# ATSAM3A4C device description
Architecture: CORTEX-M3; Family: SAM3; Series: SAM3XA
Registers are 32-bit, read-write, no defined reset value unless marked. A register's access mark holds for its fields unless they carry their own. Offsets are from the block's base; [hi:lo] are bit positions; {n}, {i} and the like mark numbered series; 'fields as' and 'values as' point back to an identical list.

## UOTGHS — USB On-The-Go Interface
Instances: UOTGHS 0x400AC000
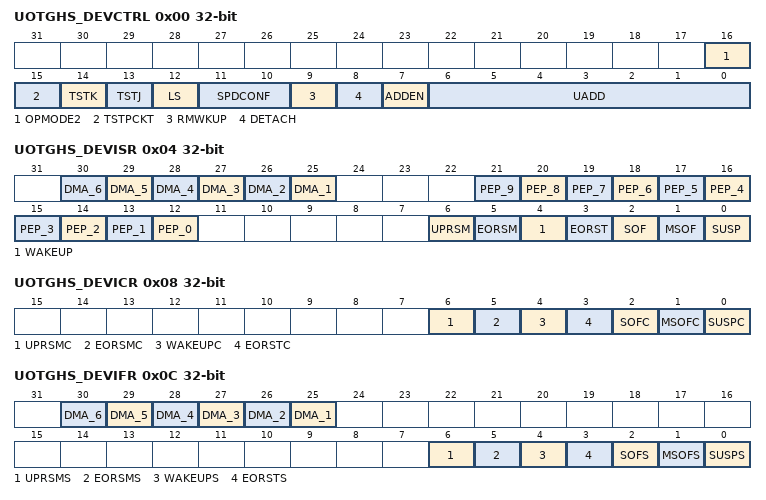
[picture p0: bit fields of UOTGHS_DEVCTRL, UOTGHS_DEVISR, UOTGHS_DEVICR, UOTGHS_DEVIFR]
0x00 UOTGHS_DEVCTRL — Device General Control Register
  [16] OPMODE2 — Specific Operational mode
  [15] TSTPCKT — Test packet mode
  [14] TSTK — Test mode K
  [13] TSTJ — Test mode J
  [12] LS — Low-Speed Mode Force
  [11:10] SPDCONF — Mode Configuration
    0=NORMAL (The peripheral starts in full-speed mode and performs a high-speed reset to switch to the high-speed mode if the host is high-speed capable.); 1=LOW_POWER (For a better consumption, if high-speed is not needed.); 2=HIGH_SPEED (Forced high speed.); 3=FORCED_FS (The peripheral remains in full-speed mode whatever the host speed capability.)
  [9] RMWKUP — Remote Wake-Up
  [8] DETACH
  [7] ADDEN — Address Enable
  [6:0] UADD — USB Address
0x04 UOTGHS_DEVISR ro — Device Global Interrupt Status Register
  [n+24] DMA_{n} (n=1..6) — DMA Channel {n} Interrupt
  [n+12] PEP_{n} (n=0..9) — Endpoint {n} Interrupt
  [6] UPRSM — Upstream Resume Interrupt
  [5] EORSM — End of Resume Interrupt
  [4] WAKEUP — Wake-Up Interrupt
  [3] EORST — End of Reset Interrupt
  [2] SOF — Start of Frame Interrupt
  [1] MSOF — Micro Start of Frame Interrupt
  [0] SUSP — Suspend Interrupt
0x08 UOTGHS_DEVICR wo — Device Global Interrupt Clear Register
  [6] UPRSMC — Upstream Resume Interrupt Clear
  [5] EORSMC — End of Resume Interrupt Clear
  [4] WAKEUPC — Wake-Up Interrupt Clear
  [3] EORSTC — End of Reset Interrupt Clear
  [2] SOFC — Start of Frame Interrupt Clear
  [1] MSOFC — Micro Start of Frame Interrupt Clear
  [0] SUSPC — Suspend Interrupt Clear
0x0C UOTGHS_DEVIFR wo — Device Global Interrupt Set Register
  [n+24] DMA_{n} (n=1..6) — DMA Channel {n} Interrupt Set
  [6] UPRSMS — Upstream Resume Interrupt Set
  [5] EORSMS — End of Resume Interrupt Set
  [4] WAKEUPS — Wake-Up Interrupt Set
  [3] EORSTS — End of Reset Interrupt Set
  [2] SOFS — Start of Frame Interrupt Set
  [1] MSOFS — Micro Start of Frame Interrupt Set
  [0] SUSPS — Suspend Interrupt Set
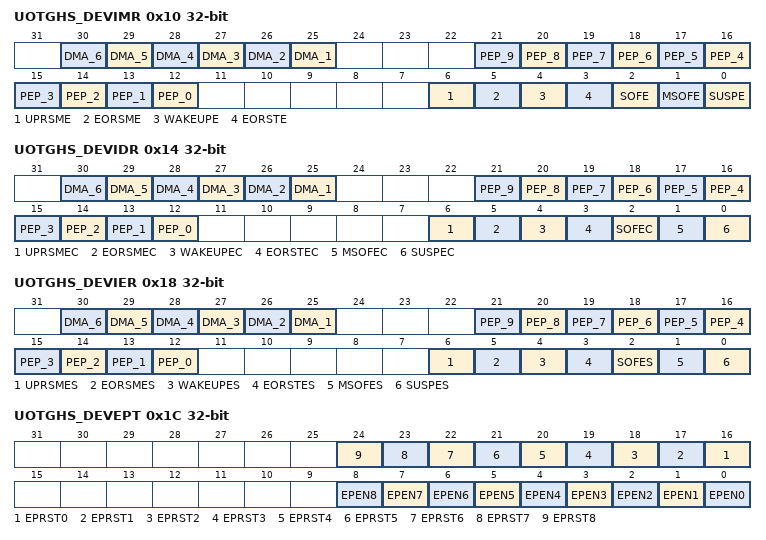
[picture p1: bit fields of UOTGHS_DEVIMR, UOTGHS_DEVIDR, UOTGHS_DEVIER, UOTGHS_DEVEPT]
0x10 UOTGHS_DEVIMR ro — Device Global Interrupt Mask Register
  [n+24] DMA_{n} (n=1..6) — DMA Channel {n} Interrupt Mask
  [n+12] PEP_{n} (n=0..9) — Endpoint {n} Interrupt Mask
  [6] UPRSME — Upstream Resume Interrupt Mask
  [5] EORSME — End of Resume Interrupt Mask
  [4] WAKEUPE — Wake-Up Interrupt Mask
  [3] EORSTE — End of Reset Interrupt Mask
  [2] SOFE — Start of Frame Interrupt Mask
  [1] MSOFE — Micro Start of Frame Interrupt Mask
  [0] SUSPE — Suspend Interrupt Mask
0x14 UOTGHS_DEVIDR wo — Device Global Interrupt Disable Register
  [n+24] DMA_{n} (n=1..6) — DMA Channel {n} Interrupt Disable
  [n+12] PEP_{n} (n=0..9) — Endpoint {n} Interrupt Disable
  [6] UPRSMEC — Upstream Resume Interrupt Disable
  [5] EORSMEC — End of Resume Interrupt Disable
  [4] WAKEUPEC — Wake-Up Interrupt Disable
  [3] EORSTEC — End of Reset Interrupt Disable
  [2] SOFEC — Start of Frame Interrupt Disable
  [1] MSOFEC — Micro Start of Frame Interrupt Disable
  [0] SUSPEC — Suspend Interrupt Disable
0x18 UOTGHS_DEVIER wo — Device Global Interrupt Enable Register
  [n+24] DMA_{n} (n=1..6) — DMA Channel {n} Interrupt Enable
  [n+12] PEP_{n} (n=0..9) — Endpoint {n} Interrupt Enable
  [6] UPRSMES — Upstream Resume Interrupt Enable
  [5] EORSMES — End of Resume Interrupt Enable
  [4] WAKEUPES — Wake-Up Interrupt Enable
  [3] EORSTES — End of Reset Interrupt Enable
  [2] SOFES — Start of Frame Interrupt Enable
  [1] MSOFES — Micro Start of Frame Interrupt Enable
  [0] SUSPES — Suspend Interrupt Enable
0x1C UOTGHS_DEVEPT — Device Endpoint Register
  [n+16] EPRST{n} (n=0..8) — Endpoint {n} Reset
  [n] EPEN{n} (n=0..8) — Endpoint {n} Enable
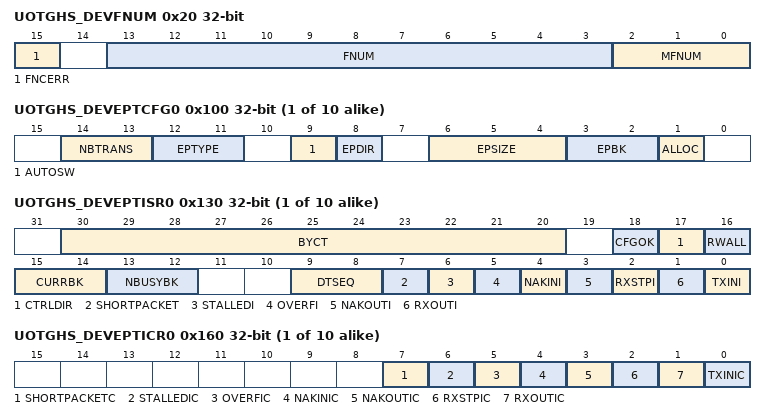
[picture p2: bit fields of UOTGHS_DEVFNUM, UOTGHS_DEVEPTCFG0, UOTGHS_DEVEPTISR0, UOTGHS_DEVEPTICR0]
0x20 UOTGHS_DEVFNUM ro — Device Frame Number Register
  [15] FNCERR — Frame Number CRC Error
  [13:3] FNUM — Frame Number
  [2:0] MFNUM — Micro Frame Number
{0x100+4i} UOTGHS_DEVEPTCFG{i} (i=0..9) — Device Endpoint Configuration Register (n = 0) {i}
  [14:13] NBTRANS — Number of transaction per microframe for isochronous endpoint
    0=_0_TRANS (reserved to endpoint that does not have the high-bandwidth isochronous capability.); 1=_1_TRANS (default value: one transaction per micro-frame.); 2=_2_TRANS (2 transactions per micro-frame. This endpoint should be configured as double-bank.); 3=_3_TRANS (3 transactions per micro-frame. This endpoint should be configured as triple-bank.)
  [12:11] EPTYPE — Endpoint Type
    0=CTRL (Control); 1=ISO (Isochronous); 2=BLK (Bulk); 3=INTRPT (Interrupt)
  [9] AUTOSW — Automatic Switch
  [8] EPDIR — Endpoint Direction
    0=OUT (The endpoint direction is OUT.); 1=IN (The endpoint direction is IN (nor for control endpoints).)
  [6:4] EPSIZE — Endpoint Size
    0=_8_BYTE (8 bytes); 1=_16_BYTE (16 bytes); 2=_32_BYTE (32 bytes); 3=_64_BYTE (64 bytes); 4=_128_BYTE (128 bytes); 5=_256_BYTE (256 bytes); 6=_512_BYTE (512 bytes); 7=_1024_BYTE (1024 bytes)
  [3:2] EPBK — Endpoint Banks
    0=_1_BANK (Single-bank endpoint); 1=_2_BANK (Double-bank endpoint); 2=_3_BANK (Triple-bank endpoint)
  [1] ALLOC — Endpoint Memory Allocate
{0x130+4i} UOTGHS_DEVEPTISR{i} ro (i=0..9) — Device Endpoint Status Register (n = 0) {i}
  [30:20] BYCT — Byte Count
  [18] CFGOK — Configuration OK Status
  [17] CTRLDIR — Control Direction
  [16] RWALL — Read-write Allowed
  [15:14] CURRBK — Current Bank
    0=BANK0 (Current bank is bank0); 1=BANK1 (Current bank is bank1); 2=BANK2 (Current bank is bank2)
  [13:12] NBUSYBK — Number of Busy Banks
    0=_0_BUSY (0 busy bank (all banks free)); 1=_1_BUSY (1 busy bank); 2=_2_BUSY (2 busy banks); 3=_3_BUSY (3 busy banks)
  [9:8] DTSEQ — Data Toggle Sequence
    0=DATA0 (Data0 toggle sequence); 1=DATA1 (Data1 toggle sequence); 2=DATA2 (Reserved for high-bandwidth isochronous endpoint); 3=MDATA (Reserved for high-bandwidth isochronous endpoint)
  [7] SHORTPACKET — Short Packet Interrupt
  [6] STALLEDI — STALLed Interrupt
  [5] OVERFI — Overflow Interrupt
  [4] NAKINI — NAKed IN Interrupt
  [3] NAKOUTI — NAKed OUT Interrupt
  [2] RXSTPI — Received SETUP Interrupt
  [1] RXOUTI — Received OUT Data Interrupt
  [0] TXINI — Transmitted IN Data Interrupt
{0x160+4i} UOTGHS_DEVEPTICR{i} wo (i=0..9) — Device Endpoint Clear Register (n = 0) {i}
  [7] SHORTPACKETC — Short Packet Interrupt Clear
  [6] STALLEDIC — STALLed Interrupt Clear
  [5] OVERFIC — Overflow Interrupt Clear
  [4] NAKINIC — NAKed IN Interrupt Clear
  [3] NAKOUTIC — NAKed OUT Interrupt Clear
  [2] RXSTPIC — Received SETUP Interrupt Clear
  [1] RXOUTIC — Received OUT Data Interrupt Clear
  [0] TXINIC — Transmitted IN Data Interrupt Clear
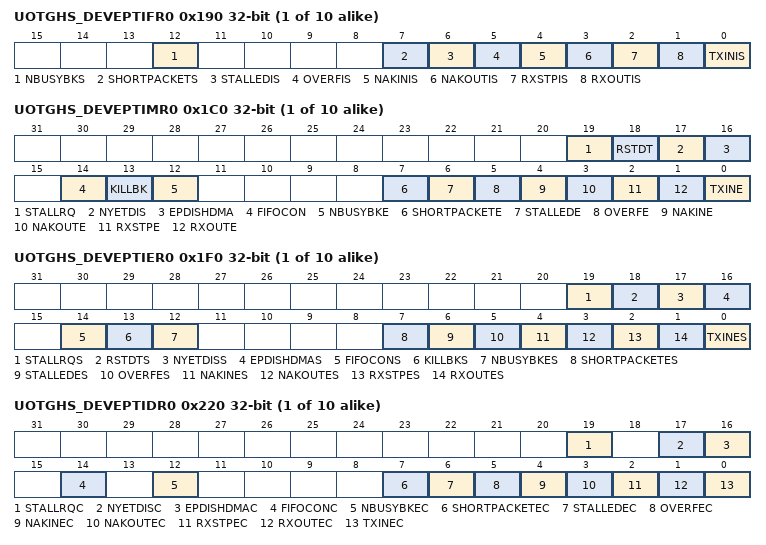
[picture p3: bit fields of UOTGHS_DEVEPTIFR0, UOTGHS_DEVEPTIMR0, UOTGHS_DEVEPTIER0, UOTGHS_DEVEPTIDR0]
{0x190+4i} UOTGHS_DEVEPTIFR{i} wo (i=0..9) — Device Endpoint Set Register (n = 0) {i}
  [12] NBUSYBKS — Number of Busy Banks Interrupt Set
  [7] SHORTPACKETS — Short Packet Interrupt Set
  [6] STALLEDIS — STALLed Interrupt Set
  [5] OVERFIS — Overflow Interrupt Set
  [4] NAKINIS — NAKed IN Interrupt Set
  [3] NAKOUTIS — NAKed OUT Interrupt Set
  [2] RXSTPIS — Received SETUP Interrupt Set
  [1] RXOUTIS — Received OUT Data Interrupt Set
  [0] TXINIS — Transmitted IN Data Interrupt Set
{0x1C0+4i} UOTGHS_DEVEPTIMR{i} ro (i=0..9) — Device Endpoint Mask Register (n = 0) {i}
  [19] STALLRQ — STALL Request
  [18] RSTDT — Reset Data Toggle
  [17] NYETDIS — NYET Token Disable
  [16] EPDISHDMA — Endpoint Interrupts Disable HDMA Request
  [14] FIFOCON — FIFO Control
  [13] KILLBK — Kill IN Bank
  [12] NBUSYBKE — Number of Busy Banks Interrupt
  [7] SHORTPACKETE — Short Packet Interrupt
  [6] STALLEDE — STALLed Interrupt
  [5] OVERFE — Overflow Interrupt
  [4] NAKINE — NAKed IN Interrupt
  [3] NAKOUTE — NAKed OUT Interrupt
  [2] RXSTPE — Received SETUP Interrupt
  [1] RXOUTE — Received OUT Data Interrupt
  [0] TXINE — Transmitted IN Data Interrupt
{0x1F0+4i} UOTGHS_DEVEPTIER{i} wo (i=0..9) — Device Endpoint Enable Register (n = 0) {i}
  [19] STALLRQS — STALL Request Enable
  [18] RSTDTS — Reset Data Toggle Enable
  [17] NYETDISS — NYET Token Disable Enable
  [16] EPDISHDMAS — Endpoint Interrupts Disable HDMA Request Enable
  [14] FIFOCONS — FIFO Control
  [13] KILLBKS — Kill IN Bank
  [12] NBUSYBKES — Number of Busy Banks Interrupt Enable
  [7] SHORTPACKETES — Short Packet Interrupt Enable
  [6] STALLEDES — STALLed Interrupt Enable
  [5] OVERFES — Overflow Interrupt Enable
  [4] NAKINES — NAKed IN Interrupt Enable
  [3] NAKOUTES — NAKed OUT Interrupt Enable
  [2] RXSTPES — Received SETUP Interrupt Enable
  [1] RXOUTES — Received OUT Data Interrupt Enable
  [0] TXINES — Transmitted IN Data Interrupt Enable
{0x220+4i} UOTGHS_DEVEPTIDR{i} wo (i=0..9) — Device Endpoint Disable Register (n = 0) {i}
  [19] STALLRQC — STALL Request Clear
  [17] NYETDISC — NYET Token Disable Clear
  [16] EPDISHDMAC — Endpoint Interrupts Disable HDMA Request Clear
  [14] FIFOCONC — FIFO Control Clear
  [12] NBUSYBKEC — Number of Busy Banks Interrupt Clear
  [7] SHORTPACKETEC — Shortpacket Interrupt Clear
  [6] STALLEDEC — STALLed Interrupt Clear
  [5] OVERFEC — Overflow Interrupt Clear
  [4] NAKINEC — NAKed IN Interrupt Clear
  [3] NAKOUTEC — NAKed OUT Interrupt Clear
  [2] RXSTPEC — Received SETUP Interrupt Clear
  [1] RXOUTEC — Received OUT Data Interrupt Clear
  [0] TXINEC — Transmitted IN Interrupt Clear
{0x300+0x10*i} UOTGHS_DEVDMANXTDSC{i} (i=1..7) — Device DMA Channel Next Descriptor Address Register (n = {i})
  [31:0] NXT_DSC_ADD — Next Descriptor Address
{0x304+0x10*i} UOTGHS_DEVDMAADDRESS{i} (i=1..7) — Device DMA Channel Address Register (n = {i})
  [31:0] BUFF_ADD — Buffer Address
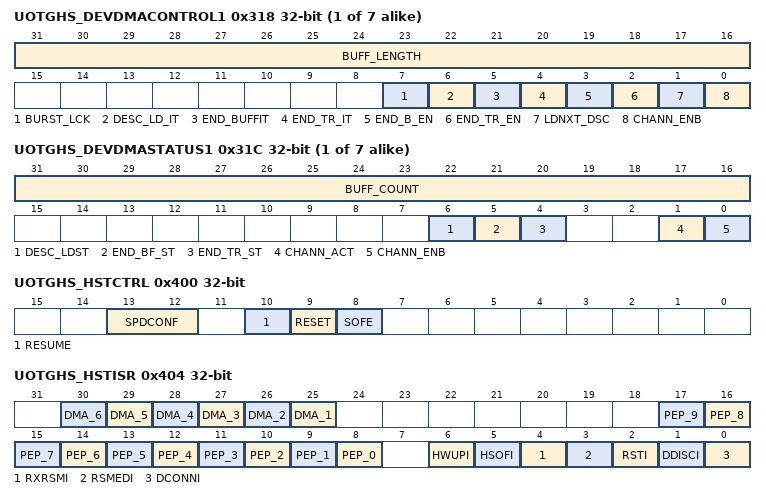
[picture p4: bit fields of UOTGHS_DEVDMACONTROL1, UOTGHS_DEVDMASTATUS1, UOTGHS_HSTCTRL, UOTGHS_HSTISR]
{0x308+0x10*i} UOTGHS_DEVDMACONTROL{i} (i=1..7) — Device DMA Channel Control Register (n = {i})
  [31:16] BUFF_LENGTH — Buffer Byte Length (Write-only)
  [7] BURST_LCK — Burst Lock Enable
  [6] DESC_LD_IT — Descriptor Loaded Interrupt Enable
  [5] END_BUFFIT — End of Buffer Interrupt Enable
  [4] END_TR_IT — End of Transfer Interrupt Enable
  [3] END_B_EN — End of Buffer Enable Control
  [2] END_TR_EN — End of Transfer Enable Control
  [1] LDNXT_DSC — Load Next Channel Transfer Descriptor Enable Command
  [0] CHANN_ENB — Channel Enable Command
{0x30C+0x10*i} UOTGHS_DEVDMASTATUS{i} (i=1..7) — Device DMA Channel Status Register (n = {i})
  [31:16] BUFF_COUNT — Buffer Byte Count
  [6] DESC_LDST — Descriptor Loaded Status
  [5] END_BF_ST — End of Channel Buffer Status
  [4] END_TR_ST — End of Channel Transfer Status
  [1] CHANN_ACT — Channel Active Status
  [0] CHANN_ENB — Channel Enable Status
0x400 UOTGHS_HSTCTRL — Host General Control Register
  [13:12] SPDCONF — Mode Configuration
    0=NORMAL (The host starts in full-speed mode and performs a high-speed reset to switch to the high-speed mode if the downstream peripheral is high-speed capable.); 1=LOW_POWER (For a better consumption, if high-speed is not needed.); 2=HIGH_SPEED (Forced high speed.); 3=FORCED_FS (The host remains to full-speed mode whatever the peripheral speed capability.)
  [10] RESUME — Send USB Resume
  [9] RESET — Send USB Reset
  [8] SOFE — Start of Frame Generation Enable
0x404 UOTGHS_HSTISR ro — Host Global Interrupt Status Register
  [n+24] DMA_{n} (n=1..6) — DMA Channel {n} Interrupt
  [n+8] PEP_{n} (n=0..9) — Pipe {n} Interrupt
  [6] HWUPI — Host Wake-Up Interrupt
  [5] HSOFI — Host Start of Frame Interrupt
  [4] RXRSMI — Upstream Resume Received Interrupt
  [3] RSMEDI — Downstream Resume Sent Interrupt
  [2] RSTI — USB Reset Sent Interrupt
  [1] DDISCI — Device Disconnection Interrupt
  [0] DCONNI — Device Connection Interrupt
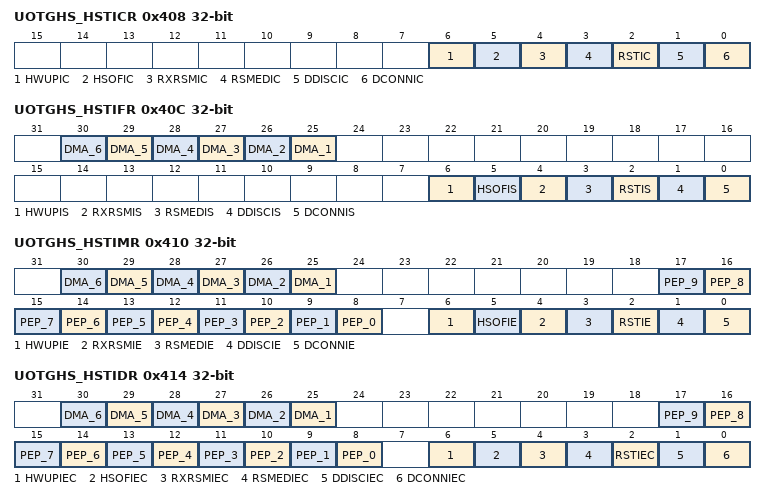
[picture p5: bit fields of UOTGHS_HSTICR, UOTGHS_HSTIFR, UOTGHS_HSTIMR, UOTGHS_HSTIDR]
0x408 UOTGHS_HSTICR wo — Host Global Interrupt Clear Register
  [6] HWUPIC — Host Wake-Up Interrupt Clear
  [5] HSOFIC — Host Start of Frame Interrupt Clear
  [4] RXRSMIC — Upstream Resume Received Interrupt Clear
  [3] RSMEDIC — Downstream Resume Sent Interrupt Clear
  [2] RSTIC — USB Reset Sent Interrupt Clear
  [1] DDISCIC — Device Disconnection Interrupt Clear
  [0] DCONNIC — Device Connection Interrupt Clear
0x40C UOTGHS_HSTIFR wo — Host Global Interrupt Set Register
  [n+24] DMA_{n} (n=1..6) — DMA Channel {n} Interrupt Set
  [6] HWUPIS — Host Wake-Up Interrupt Set
  [5] HSOFIS — Host Start of Frame Interrupt Set
  [4] RXRSMIS — Upstream Resume Received Interrupt Set
  [3] RSMEDIS — Downstream Resume Sent Interrupt Set
  [2] RSTIS — USB Reset Sent Interrupt Set
  [1] DDISCIS — Device Disconnection Interrupt Set
  [0] DCONNIS — Device Connection Interrupt Set
0x410 UOTGHS_HSTIMR ro — Host Global Interrupt Mask Register
  [n+24] DMA_{n} (n=1..6) — DMA Channel {n} Interrupt Enable
  [n+8] PEP_{n} (n=0..9) — Pipe {n} Interrupt Enable
  [6] HWUPIE — Host Wake-Up Interrupt Enable
  [5] HSOFIE — Host Start of Frame Interrupt Enable
  [4] RXRSMIE — Upstream Resume Received Interrupt Enable
  [3] RSMEDIE — Downstream Resume Sent Interrupt Enable
  [2] RSTIE — USB Reset Sent Interrupt Enable
  [1] DDISCIE — Device Disconnection Interrupt Enable
  [0] DCONNIE — Device Connection Interrupt Enable
0x414 UOTGHS_HSTIDR wo — Host Global Interrupt Disable Register
  [n+24] DMA_{n} (n=1..6) — DMA Channel {n} Interrupt Disable
  [n+8] PEP_{n} (n=0..9) — Pipe {n} Interrupt Disable
  [6] HWUPIEC — Host Wake-Up Interrupt Disable
  [5] HSOFIEC — Host Start of Frame Interrupt Disable
  [4] RXRSMIEC — Upstream Resume Received Interrupt Disable
  [3] RSMEDIEC — Downstream Resume Sent Interrupt Disable
  [2] RSTIEC — USB Reset Sent Interrupt Disable
  [1] DDISCIEC — Device Disconnection Interrupt Disable
  [0] DCONNIEC — Device Connection Interrupt Disable
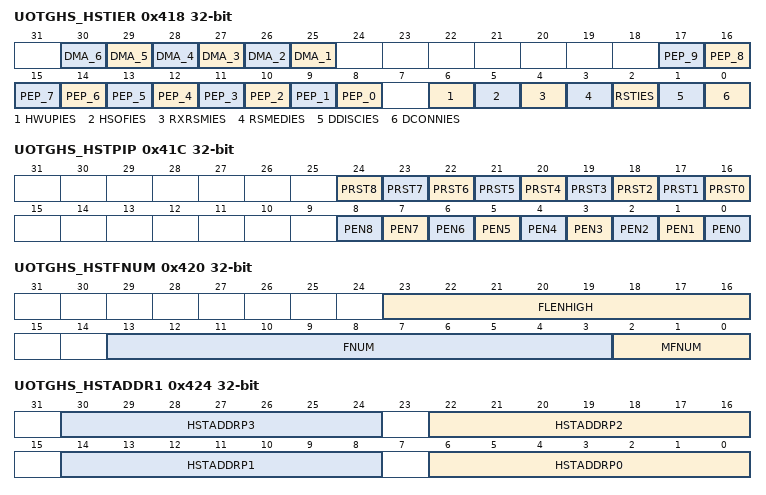
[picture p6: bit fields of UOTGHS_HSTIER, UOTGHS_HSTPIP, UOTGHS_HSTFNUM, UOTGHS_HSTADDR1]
0x418 UOTGHS_HSTIER wo — Host Global Interrupt Enable Register
  [n+24] DMA_{n} (n=1..6) — DMA Channel {n} Interrupt Enable
  [n+8] PEP_{n} (n=0..9) — Pipe {n} Interrupt Enable
  [6] HWUPIES — Host Wake-Up Interrupt Enable
  [5] HSOFIES — Host Start of Frame Interrupt Enable
  [4] RXRSMIES — Upstream Resume Received Interrupt Enable
  [3] RSMEDIES — Downstream Resume Sent Interrupt Enable
  [2] RSTIES — USB Reset Sent Interrupt Enable
  [1] DDISCIES — Device Disconnection Interrupt Enable
  [0] DCONNIES — Device Connection Interrupt Enable
0x41C UOTGHS_HSTPIP — Host Pipe Register
  [n+16] PRST{n} (n=0..8) — Pipe {n} Reset
  [n] PEN{n} (n=0..8) — Pipe {n} Enable
0x420 UOTGHS_HSTFNUM — Host Frame Number Register
  [23:16] FLENHIGH — Frame Length
  [13:3] FNUM — Frame Number
  [2:0] MFNUM — Micro Frame Number
0x424 UOTGHS_HSTADDR1 — Host Address 1 Register
  [8n+6:8n] HSTADDRP{n} (n=0..3) — USB Host Address
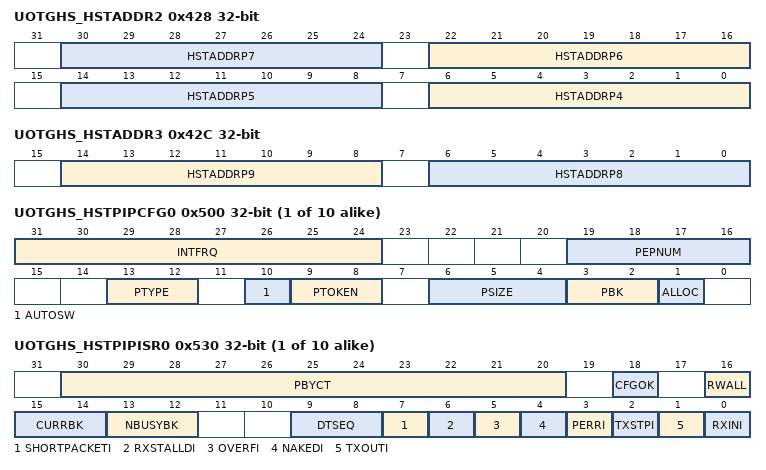
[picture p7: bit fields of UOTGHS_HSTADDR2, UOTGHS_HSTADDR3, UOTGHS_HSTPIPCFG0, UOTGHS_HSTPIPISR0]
0x428 UOTGHS_HSTADDR2 — Host Address 2 Register
  [8n-26:8n-32] HSTADDRP{n} (n=4..7) — USB Host Address
0x42C UOTGHS_HSTADDR3 — Host Address 3 Register
  [14:8] HSTADDRP9 — USB Host Address
  [6:0] HSTADDRP8 — USB Host Address
{0x500+4i} UOTGHS_HSTPIPCFG{i} (i=0..9) — Host Pipe Configuration Register (n = 0) {i}
  [31:24] INTFRQ — Pipe Interrupt Request Frequency
  [19:16] PEPNUM — Pipe Endpoint Number
  [13:12] PTYPE — Pipe Type
    values as UOTGHS_DEVEPTCFG0.EPTYPE
  [10] AUTOSW — Automatic Switch
  [9:8] PTOKEN — Pipe Token
    0=SETUP; 1=IN; 2=OUT
  [6:4] PSIZE — Pipe Size
    values as UOTGHS_DEVEPTCFG0.EPSIZE
  [3:2] PBK — Pipe Banks
    0=_1_BANK (Single-bank pipe); 1=_2_BANK (Double-bank pipe); 2=_3_BANK (Triple-bank pipe)
  [1] ALLOC — Pipe Memory Allocate
{0x530+4i} UOTGHS_HSTPIPISR{i} ro (i=0..9) — Host Pipe Status Register (n = 0) {i}
  [30:20] PBYCT — Pipe Byte Count
  [18] CFGOK — Configuration OK Status
  [16] RWALL — Read-write Allowed
  [15:14] CURRBK — Current Bank
    values as UOTGHS_DEVEPTISR0.CURRBK
  [13:12] NBUSYBK — Number of Busy Banks
    values as UOTGHS_DEVEPTISR0.NBUSYBK
  [9:8] DTSEQ — Data Toggle Sequence
    0=DATA0 (Data0 toggle sequence); 1=DATA1 (Data1 toggle sequence)
  [7] SHORTPACKETI — Short Packet Interrupt
  [6] RXSTALLDI — Received STALLed Interrupt
  [5] OVERFI — Overflow Interrupt
  [4] NAKEDI — NAKed Interrupt
  [3] PERRI — Pipe Error Interrupt
  [2] TXSTPI — Transmitted SETUP Interrupt
  [1] TXOUTI — Transmitted OUT Data Interrupt
  [0] RXINI — Received IN Data Interrupt
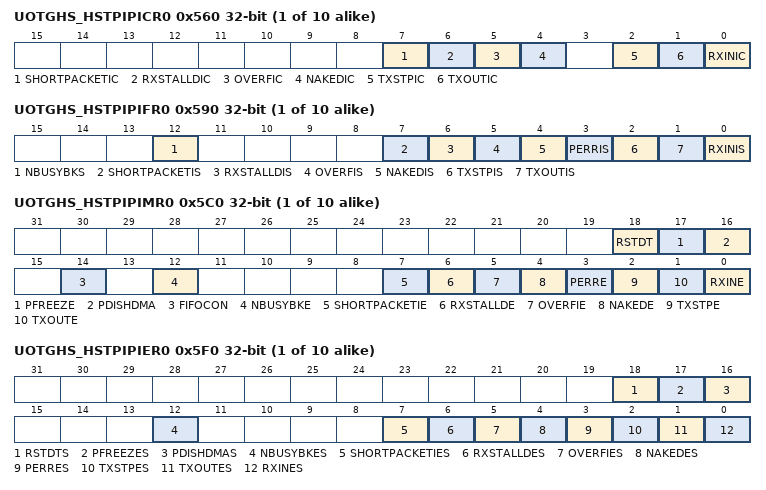
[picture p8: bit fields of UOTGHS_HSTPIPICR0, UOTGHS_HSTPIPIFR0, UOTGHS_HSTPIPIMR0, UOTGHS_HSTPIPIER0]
{0x560+4i} UOTGHS_HSTPIPICR{i} wo (i=0..9) — Host Pipe Clear Register (n = 0) {i}
  [7] SHORTPACKETIC — Short Packet Interrupt Clear
  [6] RXSTALLDIC — Received STALLed Interrupt Clear
  [5] OVERFIC — Overflow Interrupt Clear
  [4] NAKEDIC — NAKed Interrupt Clear
  [2] TXSTPIC — Transmitted SETUP Interrupt Clear
  [1] TXOUTIC — Transmitted OUT Data Interrupt Clear
  [0] RXINIC — Received IN Data Interrupt Clear
{0x590+4i} UOTGHS_HSTPIPIFR{i} wo (i=0..9) — Host Pipe Set Register (n = 0) {i}
  [12] NBUSYBKS — Number of Busy Banks Set
  [7] SHORTPACKETIS — Short Packet Interrupt Set
  [6] RXSTALLDIS — Received STALLed Interrupt Set
  [5] OVERFIS — Overflow Interrupt Set
  [4] NAKEDIS — NAKed Interrupt Set
  [3] PERRIS — Pipe Error Interrupt Set
  [2] TXSTPIS — Transmitted SETUP Interrupt Set
  [1] TXOUTIS — Transmitted OUT Data Interrupt Set
  [0] RXINIS — Received IN Data Interrupt Set
{0x5C0+4i} UOTGHS_HSTPIPIMR{i} ro (i=0..9) — Host Pipe Mask Register (n = 0) {i}
  [18] RSTDT — Reset Data Toggle
  [17] PFREEZE — Pipe Freeze
  [16] PDISHDMA — Pipe Interrupts Disable HDMA Request Enable
  [14] FIFOCON — FIFO Control
  [12] NBUSYBKE — Number of Busy Banks Interrupt Enable
  [7] SHORTPACKETIE — Short Packet Interrupt Enable
  [6] RXSTALLDE — Received STALLed Interrupt Enable
  [5] OVERFIE — Overflow Interrupt Enable
  [4] NAKEDE — NAKed Interrupt Enable
  [3] PERRE — Pipe Error Interrupt Enable
  [2] TXSTPE — Transmitted SETUP Interrupt Enable
  [1] TXOUTE — Transmitted OUT Data Interrupt Enable
  [0] RXINE — Received IN Data Interrupt Enable
{0x5F0+4i} UOTGHS_HSTPIPIER{i} wo (i=0..9) — Host Pipe Enable Register (n = 0) {i}
  [18] RSTDTS — Reset Data Toggle Enable
  [17] PFREEZES — Pipe Freeze Enable
  [16] PDISHDMAS — Pipe Interrupts Disable HDMA Request Enable
  [12] NBUSYBKES — Number of Busy Banks Enable
  [7] SHORTPACKETIES — Short Packet Interrupt Enable
  [6] RXSTALLDES — Received STALLed Interrupt Enable
  [5] OVERFIES — Overflow Interrupt Enable
  [4] NAKEDES — NAKed Interrupt Enable
  [3] PERRES — Pipe Error Interrupt Enable
  [2] TXSTPES — Transmitted SETUP Interrupt Enable
  [1] TXOUTES — Transmitted OUT Data Interrupt Enable
  [0] RXINES — Received IN Data Interrupt Enable
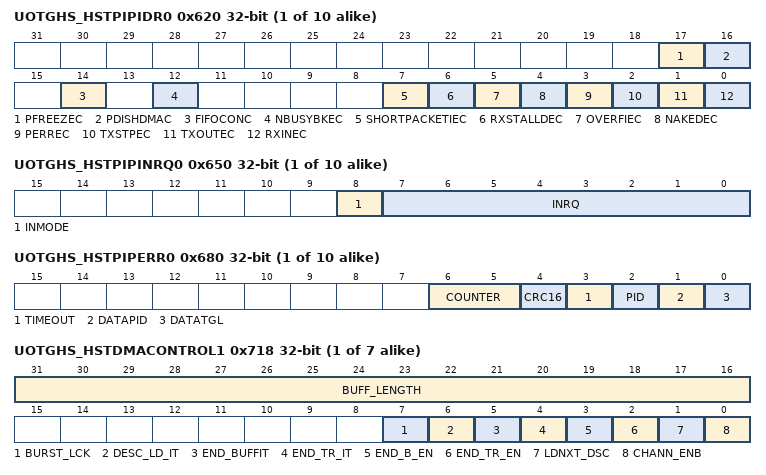
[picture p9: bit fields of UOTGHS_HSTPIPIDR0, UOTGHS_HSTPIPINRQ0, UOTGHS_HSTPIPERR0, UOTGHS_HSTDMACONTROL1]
{0x620+4i} UOTGHS_HSTPIPIDR{i} wo (i=0..9) — Host Pipe Disable Register (n = 0) {i}
  [17] PFREEZEC — Pipe Freeze Disable
  [16] PDISHDMAC — Pipe Interrupts Disable HDMA Request Disable
  [14] FIFOCONC — FIFO Control Disable
  [12] NBUSYBKEC — Number of Busy Banks Disable
  [7] SHORTPACKETIEC — Short Packet Interrupt Disable
  [6] RXSTALLDEC — Received STALLed Interrupt Disable
  [5] OVERFIEC — Overflow Interrupt Disable
  [4] NAKEDEC — NAKed Interrupt Disable
  [3] PERREC — Pipe Error Interrupt Disable
  [2] TXSTPEC — Transmitted SETUP Interrupt Disable
  [1] TXOUTEC — Transmitted OUT Data Interrupt Disable
  [0] RXINEC — Received IN Data Interrupt Disable
{0x650+4i} UOTGHS_HSTPIPINRQ{i} (i=0..9) — Host Pipe IN Request Register (n = 0) {i}
  [8] INMODE — IN Request Mode
  [7:0] INRQ — IN Request Number before Freeze
{0x680+4i} UOTGHS_HSTPIPERR{i} (i=0..9) — Host Pipe Error Register (n = 0) {i}
  [6:5] COUNTER — Error Counter
  [4] CRC16 — CRC16 Error
  [3] TIMEOUT — Time-Out Error
  [2] PID — PID Error
  [1] DATAPID — Data PID Error
  [0] DATATGL — Data Toggle Error
{0x700+0x10*i} UOTGHS_HSTDMANXTDSC{i} (i=1..7) — Host DMA Channel Next Descriptor Address Register (n = {i})
  [31:0] NXT_DSC_ADD — Next Descriptor Address
{0x704+0x10*i} UOTGHS_HSTDMAADDRESS{i} (i=1..7) — Host DMA Channel Address Register (n = {i})
  [31:0] BUFF_ADD — Buffer Address
{0x708+0x10*i} UOTGHS_HSTDMACONTROL{i} (i=1..7) — Host DMA Channel Control Register (n = {i})
  [31:16] BUFF_LENGTH — Buffer Byte Length (Write-only)
  [7] BURST_LCK — Burst Lock Enable
  [6] DESC_LD_IT — Descriptor Loaded Interrupt Enable
  [5] END_BUFFIT — End of Buffer Interrupt Enable
  [4] END_TR_IT — End of Transfer Interrupt Enable
  [3] END_B_EN — End of Buffer Enable Control
  [2] END_TR_EN — End of Transfer Enable (Control)
  [1] LDNXT_DSC — Load Next Channel Transfer Descriptor Enable Command
  [0] CHANN_ENB — Channel Enable Command
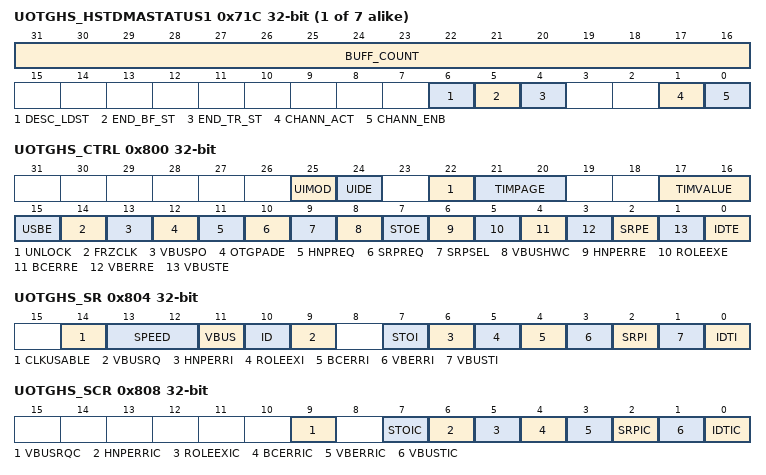
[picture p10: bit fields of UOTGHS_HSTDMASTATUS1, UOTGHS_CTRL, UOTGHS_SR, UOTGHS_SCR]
{0x70C+0x10*i} UOTGHS_HSTDMASTATUS{i} (i=1..7) — Host DMA Channel Status Register (n = {i})
  fields as UOTGHS_DEVDMASTATUS1
0x800 UOTGHS_CTRL — General Control Register
  [25] UIMOD — UOTGHS Mode
    0=HOST (The module is in USB host mode.); 1=DEVICE (The module is in USB device mode.)
  [24] UIDE — UOTGID Pin Enable
    0=UIMOD (The USB mode (device/host) is selected from the UIMOD bit.); 1=UOTGID (The USB mode (device/host) is selected from the UOTGID input pin.)
  [22] UNLOCK — Timer Access Unlock
  [21:20] TIMPAGE — Timer Page
  [17:16] TIMVALUE — Timer Value
  [15] USBE — UOTGHS Enable
  [14] FRZCLK — Freeze USB Clock
  [13] VBUSPO — VBus Polarity Off
  [12] OTGPADE — OTG Pad Enable
  [11] HNPREQ — HNP Request
  [10] SRPREQ — SRP Request
  [9] SRPSEL — SRP Selection
  [8] VBUSHWC — VBus Hardware Control
  [7] STOE — Suspend Time-Out Interrupt Enable
  [6] HNPERRE — HNP Error Interrupt Enable
  [5] ROLEEXE — Role Exchange Interrupt Enable
  [4] BCERRE — B-Connection Error Interrupt Enable
  [3] VBERRE — VBus Error Interrupt Enable
  [2] SRPE — SRP Interrupt Enable
  [1] VBUSTE — VBus Transition Interrupt Enable
  [0] IDTE — ID Transition Interrupt Enable
0x804 UOTGHS_SR ro — General Status Register
  [14] CLKUSABLE — UTMI Clock Usable
  [13:12] SPEED — Speed Status
    0=FULL_SPEED (Full-Speed mode); 1=HIGH_SPEED (High-Speed mode); 2=LOW_SPEED (Low-Speed mode)
  [11] VBUS — VBus Level
  [10] ID — UOTGID Pin State
  [9] VBUSRQ — VBus Request
  [7] STOI — Suspend Time-Out Interrupt
  [6] HNPERRI — HNP Error Interrupt
  [5] ROLEEXI — Role Exchange Interrupt
  [4] BCERRI — B-Connection Error Interrupt
  [3] VBERRI — VBus Error Interrupt
  [2] SRPI — SRP Interrupt
  [1] VBUSTI — VBus Transition Interrupt
  [0] IDTI — ID Transition Interrupt
0x808 UOTGHS_SCR wo — General Status Clear Register
  [9] VBUSRQC — VBus Request Clear
  [7] STOIC — Suspend Time-Out Interrupt Clear
  [6] HNPERRIC — HNP Error Interrupt Clear
  [5] ROLEEXIC — Role Exchange Interrupt Clear
  [4] BCERRIC — B-Connection Error Interrupt Clear
  [3] VBERRIC — VBus Error Interrupt Clear
  [2] SRPIC — SRP Interrupt Clear
  [1] VBUSTIC — VBus Transition Interrupt Clear
  [0] IDTIC — ID Transition Interrupt Clear
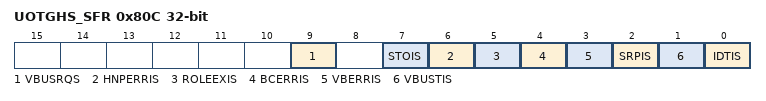
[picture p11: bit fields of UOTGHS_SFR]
0x80C UOTGHS_SFR wo — General Status Set Register
  [9] VBUSRQS — VBus Request Set
  [7] STOIS — Suspend Time-Out Interrupt Set
  [6] HNPERRIS — HNP Error Interrupt Set
  [5] ROLEEXIS — Role Exchange Interrupt Set
  [4] BCERRIS — B-Connection Error Interrupt Set
  [3] VBERRIS — VBus Error Interrupt Set
  [2] SRPIS — SRP Interrupt Set
  [1] VBUSTIS — VBus Transition Interrupt Set
  [0] IDTIS — ID Transition Interrupt Set
0x82C UOTGHS_FSM ro — General Finite State Machine Register
  [3:0] DRDSTATE — Dual Role Device State
    0=A_IDLESTATE (This is the start state for A-devices (when the ID pin is 0)); 1=A_WAIT_VRISE (In this state, the A-device waits for the voltage on VBus to rise above the A-device VBus Valid threshold (4.4 V).); 2=A_WAIT_BCON (In this state, the A-device waits for the B-device to signal a connection.); 3=A_HOST (In this state, the A-device that operates in Host mode is operational.); 4=A_SUSPEND (The A-device operating as a host is in the suspend mode.); 5=A_PERIPHERAL (The A-device operates as a peripheral.); 6=A_WAIT_VFALL (In this state, the A-device waits for the voltage on VBus to drop below the A-device Session Valid threshold (1.4 V).); 7=A_VBUS_ERR (In this state, the A-device waits for recovery of the over-current condition that caused it to enter this state.); 8=A_WAIT_DISCHARGE (In this state, the A-device waits for the data USB line to discharge (100 us).); 9=B_IDLE (This is the start state for B-device (when the ID pin is 1).); 10=B_PERIPHERAL (In this state, the B-device acts as the peripheral.); 11=B_WAIT_BEGIN_HNP (In this state, the B-device is in suspend mode and waits until 3 ms before initiating the HNP protocol if requested.); 12=B_WAIT_DISCHARGE (In this state, the B-device waits for the data USB line to discharge (100 us) before becoming Host.); 13=B_WAIT_ACON (In this state, the B-device waits for the A-device to signal a connect before becoming B-Host.); 14=B_HOST (In this state, the B-device acts as the Host.); 15=B_SRP_INIT (In this state, the B-device attempts to start a session using the SRP protocol.)

## Notices in the file
SAM Software Package License
Copyright (c) %copyright_year%, Atmel Corporation
All rights reserved.
Redistribution and use in source and binary forms, with or without
modification, are permitted provided that the following condition is met:
- Redistributions of source code must retain the above copyright notice,
this list of conditions and the disclaimer below.
Atmel's name may not be used to endorse or promote products derived from
this software without specific prior written permission.
DISCLAIMER:  THIS SOFTWARE IS PROVIDED BY ATMEL "AS IS" AND ANY EXPRESS OR
IMPLIED WARRANTIES, INCLUDING, BUT NOT LIMITED TO, THE IMPLIED WARRANTIES OF
MERCHANTABILITY, FITNESS FOR A PARTICULAR PURPOSE AND NON-INFRINGEMENT ARE
DISCLAIMED. IN NO EVENT SHALL ATMEL BE LIABLE FOR ANY DIRECT, INDIRECT,
INCIDENTAL, SPECIAL, EXEMPLARY, OR CONSEQUENTIAL DAMAGES (INCLUDING, BUT NOT
LIMITED TO, PROCUREMENT OF SUBSTITUTE GOODS OR SERVICES; LOSS OF USE, DATA,
OR PROFITS; OR BUSINESS INTERRUPTION) HOWEVER CAUSED AND ON ANY THEORY OF
LIABILITY, WHETHER IN CONTRACT, STRICT LIABILITY, OR TORT (INCLUDING
NEGLIGENCE OR OTHERWISE) ARISING IN ANY WAY OUT OF THE USE OF THIS SOFTWARE,
EVEN IF ADVISED OF THE POSSIBILITY OF SUCH DAMAGE.
